# LIS331EB register map
Vendor: STMicroelectronics; Series: LIS331EB; File version: 1.0
CPU: CM0 r0p0, little endian, no MPU, no FPU, 5 interrupt priority bits
Registers are 32-bit, read-write, reset 0x0 unless marked. A register's access mark holds for its fields unless they carry their own. Offsets are from the block's base; [hi:lo] are bit positions; lines under a group give offsets from that group; 'fields as' and 'values as' point back to an identical list.

## FLASH — Flash Controller
Base 0xA1000000
0x00 COMMAND 8-bit — Commands for the module
  [7:0] COMMAND — Command value
    17=ERASE (Erase page defined by register ADDRESS); 34=MASSERASE (Mass erase (flash is completely erased)); 51=WRITE (Program one location (defined by registers DATA and ADDRESS)); 68=MASSWRITE (Program all locations. With the same value (DATA register value)); 85=MASSREAD (Read all locations and compare with DATA register value or produce LFSR signature); 102=IFRERASE (Erase the complete 2Kbytes page); 119=IFRWRITE (Write the value DATA (@0xA100_0014) in address located in (@0XA100_0018), address space can take only 512 values of 32 bits (1 2Kbytes page) for the information block (IFR)); 136=IFRMASSWRITE (Write the 32 bits value of (@0xA100_0014) at all location of the 512 addresses); 153=IFRMASSREAD (Read the content of IFR block (512 address of 32 bits) and sign it with LFSR in @0xA100_0024); 170=SLEEP (Put flash in sleep mode); 187=WAKEUP (Get flash out of sleep mode)
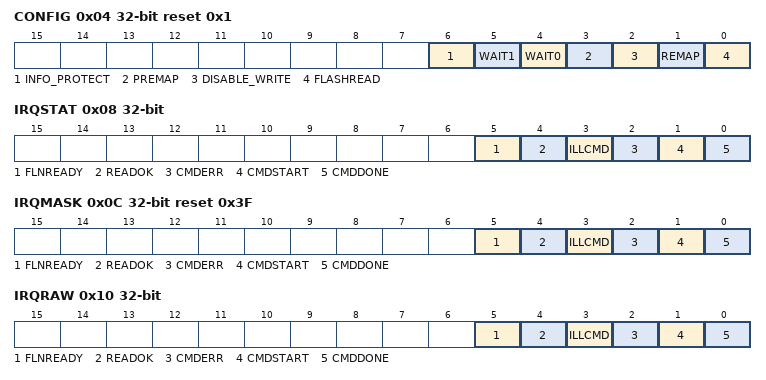
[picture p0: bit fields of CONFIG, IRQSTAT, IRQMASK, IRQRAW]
0x04 CONFIG reset 0x1 (reset mask 0x7) — Configure the wrapper
  [6] INFO_PROTECT — Write only once to disable access to info block
  [5] WAIT1 — Wait states for high clock speed
  [4] WAIT0 — Wait states for high clock speed above 16Mhz
  [3] PREMAP — Premap bit for toplevel use
  [2] DISABLE_WRITE — Disable group write
  [1] REMAP — Remap bit for toplevel use
  [0] FLASHREAD
    0=1CLK (Read access of 1 system clock); 1=2CLK (Read access of 2 system clocks with registered value)
0x08 IRQSTAT write-clears read-clears — Flash status interrupts (masked)
  [5] FLNREADY — Flash not ready (sleep)
  [4] READOK — Mass read was OK
  [3] ILLCMD — Illegal command written
  [2] CMDERR — Command written while BUSY
  [1] CMDSTART — Command is started
  [0] CMDDONE — Command is done
0x0C IRQMASK reset 0x3F — Mask for interrupts
  fields as IRQSTAT
0x10 IRQRAW write-clears read-clears — Flash status interrupts (unmasked)
  fields as IRQSTAT
0x14 DATA — Program cycle data
0x18 ADDRESS — Address for programming flash, will auto increment. One bit for IFR selection
  [13:0] ADR — Addresses 64 words within one row
0x1C UNLOCKM reset 0xFFFFFFFF — Unlock codeword (MSW). When testmode is active, the flash needs to be protected with an unlock code
0x20 UNLOCKL reset 0xFFFFFFFF — Unlock codeword (LSW). When testmode is active, the flash needs to be protected with an unlock code
0x24 LFSRVAL ro reset 0xFFFFFFFF — LFSR register needed for check after MASS READ command
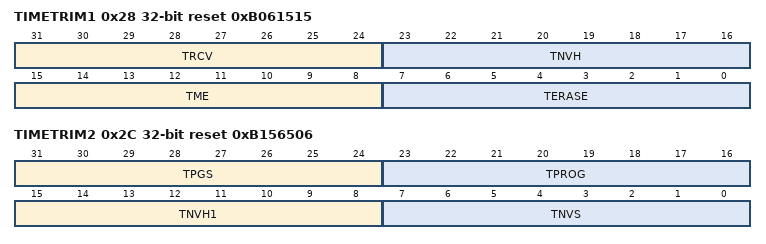
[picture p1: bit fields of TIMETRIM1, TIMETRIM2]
0x28 TIMETRIM1 reset 0xB061515 — Programmable timing register
  [31:24] TRCV, [23:16] TNVH, [15:8] TME, [7:0] TERASE
0x2C TIMETRIM2 reset 0xB156506 — Programmable timing register
  [31:24] TPGS, [23:16] TPROG, [15:8] TNVH1, [7:0] TNVS
0x30 TIMETRIM3 8-bit reset 0x11 — Programmable timing register
  [7:0] TWK

## TIMER0
Base 0xA6000000
Same registers: TIMER1 0xA7000000, TIMER2 0xA8000000, TIMER3 0xA9000000
0x04 RTT_IMSC — RTT interrupt mask register
  [0] RTT_IMSC — RTT timer interrupt enable bit
0x08 RTT_RIS ro — RTT raw interrupt status register
  [0] RTT_RIS — RTT timer raw interrupt status bit
0x0C RTT_MIS ro — RTT masked interrupt status register
  [0] RTT_MIS — RTT timer masked interrupt status bit
0x10 RTT_ICR wo write-1-clears — RTT interrupt clear register
  [0] RTT_IC — RTT timer interrupt clear register bit
0x14 RTT_DR ro — RTT data register
  [31:0] RTT_TIMER_COUNTER_VALUE — RTT current value
0x18 RTT_LR — RTC load register
  [31:0] RTT_TIMER_LOAD_VALUE — RTT load value
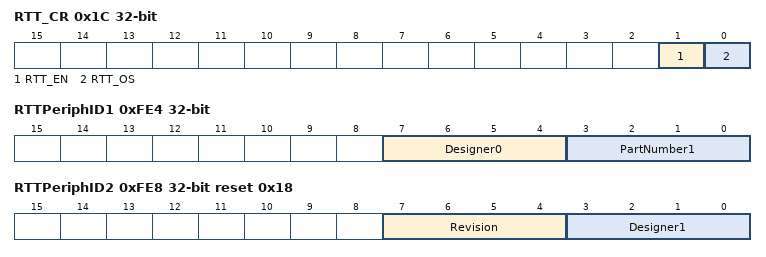
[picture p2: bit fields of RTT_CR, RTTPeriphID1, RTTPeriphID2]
0x1C RTT_CR — RTT control register
  [1] RTT_EN — RTT enable bit
  [0] RTT_OS — RTT one shot count
0x80 RTT_ITCR — Integration test control register
  [0] ITEN — Integration test enable bit
0x84 RTT_ITOP — Integration test output register
  [0] RTT_INTR — RTT_INTR output value
0xFE0 RTTPeriphID0 ro reset 0x31 — RTT peripheral identification register 0
  [7:0] PartNumber0 — These bits read back as 0x31
0xFE4 RTTPeriphID1 ro — RTT peripheral identification register 1
  [7:4] Designer0 — These bits read back as 0x00
  [3:0] PartNumber1 — These bits read back as 0x00
0xFE8 RTTPeriphID2 ro reset 0x18 — RTT peripheral identification register 2
  [7:4] Revision — These bits read back as 0x01
  [3:0] Designer1 — These bits read back as 0x08
0xFEC RTTPeriphID3 ro — RTT peripheral identification register 3
  [7:0] Configuration — These bits read back as 0x00
0xFF0 RTTPCellID0 ro reset 0xD — RTT PCell identification register 0
  [7:0] RTTPCellID0 — These bits read back as 0x0D
0xFF4 RTTPCellID1 ro reset 0x5 — RTT PCell identification register 1
  [7:0] RTTPCellID1 — These bits read back as 0x05
0xFF8 RTTPCellID2 ro reset 0x5 — RTT PCell identification register 2
  [7:0] RTTPCellID2 — These bits read back as 0x05
0xFFC RTTPCellID3 ro reset 0xB1 — RTT PCell identification register 3
  [7:0] RTTPCellID3 — These bits read back as 0xB1
